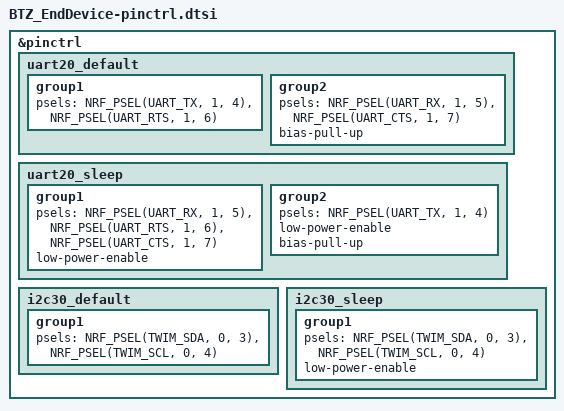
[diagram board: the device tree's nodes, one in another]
/*
 * Copyright (c) 2026 Goodbyte
 * SPDX-License-Identifier: Apache-2.0
 */

&pinctrl {
	uart20_default: uart20_default {
		group1 {
			psels = <NRF_PSEL(UART_TX, 1, 4)>,
				<NRF_PSEL(UART_RTS, 1, 6)>;
		};

		group2 {
			psels = <NRF_PSEL(UART_RX, 1, 5)>,
				<NRF_PSEL(UART_CTS, 1, 7)>;
			bias-pull-up;
		};
	};

	uart20_sleep: uart20_sleep {
		group1 {
			psels = <NRF_PSEL(UART_RX, 1, 5)>,
				<NRF_PSEL(UART_RTS, 1, 6)>,
				<NRF_PSEL(UART_CTS, 1, 7)>;
			low-power-enable;
		};

		group2 {
			psels = <NRF_PSEL(UART_TX, 1, 4)>;
			low-power-enable;
			bias-pull-up;
		};
	};

	i2c30_default: i2c30_default {
		group1 {
			psels = <NRF_PSEL(TWIM_SDA, 0, 3)>,
				<NRF_PSEL(TWIM_SCL, 0, 4)>;
		};
	};

	i2c30_sleep: i2c30_sleep {
		group1 {
			psels = <NRF_PSEL(TWIM_SDA, 0, 3)>,
				<NRF_PSEL(TWIM_SCL, 0, 4)>;
			low-power-enable;
		};
	};
};
